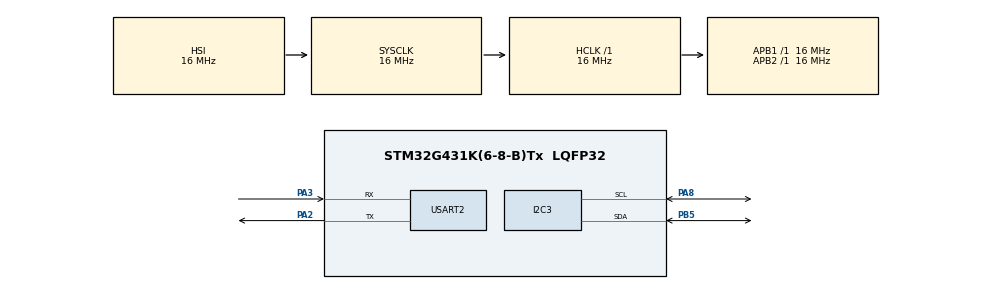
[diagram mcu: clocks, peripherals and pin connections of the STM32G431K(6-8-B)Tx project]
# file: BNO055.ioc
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Dma.I2C3_RX.0.Direction=DMA_PERIPH_TO_MEMORY
Dma.I2C3_RX.0.EventEnable=DISABLE
Dma.I2C3_RX.0.Instance=DMA1_Channel1
Dma.I2C3_RX.0.MemDataAlignment=DMA_MDATAALIGN_BYTE
Dma.I2C3_RX.0.MemInc=DMA_MINC_ENABLE
Dma.I2C3_RX.0.Mode=DMA_NORMAL
Dma.I2C3_RX.0.PeriphDataAlignment=DMA_PDATAALIGN_BYTE
Dma.I2C3_RX.0.PeriphInc=DMA_PINC_DISABLE
Dma.I2C3_RX.0.Polarity=HAL_DMAMUX_REQ_GEN_RISING
Dma.I2C3_RX.0.Priority=DMA_PRIORITY_LOW
Dma.I2C3_RX.0.RequestNumber=1
Dma.I2C3_RX.0.SignalID=NONE
Dma.I2C3_RX.0.SyncEnable=DISABLE
Dma.I2C3_RX.0.SyncPolarity=HAL_DMAMUX_SYNC_NO_EVENT
Dma.I2C3_RX.0.SyncRequestNumber=1
Dma.I2C3_RX.0.SyncSignalID=NONE
Dma.I2C3_TX.1.Direction=DMA_MEMORY_TO_PERIPH
Dma.I2C3_TX.1.EventEnable=DISABLE
Dma.I2C3_TX.1.Instance=DMA1_Channel2
Dma.I2C3_TX.1.MemDataAlignment=DMA_MDATAALIGN_BYTE
Dma.I2C3_TX.1.MemInc=DMA_MINC_ENABLE
Dma.I2C3_TX.1.Mode=DMA_NORMAL
Dma.I2C3_TX.1.PeriphDataAlignment=DMA_PDATAALIGN_BYTE
Dma.I2C3_TX.1.PeriphInc=DMA_PINC_DISABLE
Dma.I2C3_TX.1.Polarity=HAL_DMAMUX_REQ_GEN_RISING
Dma.I2C3_TX.1.Priority=DMA_PRIORITY_LOW
Dma.I2C3_TX.1.RequestNumber=1
Dma.I2C3_TX.1.SignalID=NONE
Dma.I2C3_TX.1.SyncEnable=DISABLE
Dma.I2C3_TX.1.SyncPolarity=HAL_DMAMUX_SYNC_NO_EVENT
Dma.I2C3_TX.1.SyncRequestNumber=1
Dma.I2C3_TX.1.SyncSignalID=NONE
Dma.Request0=I2C3_RX
Dma.Request1=I2C3_TX
Mcu.Family=STM32G4
Mcu.Name=STM32G431K(6-8-B)Tx
Mcu.Package=LQFP32
NVIC.DMA1_Channel1_IRQn=true\:0\:0\:false\:false\:true\:false\:true\:true
NVIC.DMA1_Channel2_IRQn=true\:0\:0\:false\:false\:true\:false\:true\:true
NVIC.PriorityGroup=NVIC_PRIORITYGROUP_4
PA2.Mode=Asynchronous
PA2.Signal=USART2_TX
PA3.Mode=Asynchronous
PA3.Signal=USART2_RX
PA8.Mode=I2C
PA8.Signal=I2C3_SCL
PB5.Mode=I2C
PB5.Signal=I2C3_SDA
ProjectManager.HeapSize=0x200
ProjectManager.StackSize=0x400
ProjectManager.TargetToolchain=STM32CubeIDE
RCC.AHBFreq_Value=16000000
RCC.APB1Freq_Value=16000000
RCC.APB1TimFreq_Value=16000000
RCC.APB2Freq_Value=16000000
RCC.APB2TimFreq_Value=16000000
RCC.CortexFreq_Value=16000000
RCC.EXTERNAL_CLOCK_VALUE=12288000
RCC.HCLKFreq_Value=16000000
RCC.HSE_VALUE=8000000
RCC.HSI48_VALUE=48000000
RCC.HSI_VALUE=16000000
RCC.LSE_VALUE=32768
RCC.SYSCLKFreq_VALUE=16000000
RCC.USBFreq_Value=64000000
RCC.VCOOutputFreq_Value=128000000
USART2.VirtualMode-Asynchronous=VM_ASYNC
board=custom

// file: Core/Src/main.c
/* USER CODE BEGIN Header */
/**
  ******************************************************************************
  * @file           : main.c
  * @brief          : Main program body
  ******************************************************************************
  * @attention
  *
  * Copyright (c) 2023 STMicroelectronics.
  * All rights reserved.
  *
  * This software is licensed under terms that can be found in the LICENSE file
  * in the root directory of this software component.
  * If no LICENSE file comes with this software, it is provided AS-IS.
  *
  ******************************************************************************
  */
/* USER CODE END Header */
#include "main.h"
#include "dma.h"
#include "i2c.h"
#include "usart.h"
#include "gpio.h"

/* USER CODE BEGIN Includes */
#include <stdio.h>
#include "bno055_stm32.h"
#ifdef __GNUC__
#define PUTCHAR_PROTOTYPE int __io_putchar(int ch)
#else
#define PUTCHAR_PROTOTYPE int fputc(int ch, FILE *f)
#endif
PUTCHAR_PROTOTYPE

{

HAL_UART_Transmit(&huart2, (uint8_t *)&ch, 1, HAL_MAX_DELAY);

return ch;

}

/* USER CODE END Includes */

void SystemClock_Config(void);
/* USER CODE BEGIN PFP */

//#ifdef __GNUC__
//#define PUTCHAR_PROTOTYPE int __io_putchar(int ch)
//#else
//#define PUTCHAR_PROTOTYPE int fputc(int ch, FILE *f)
//#endif
//
//PUTCHAR_PROTOTYPE
//
//{
//
//	HAL_UART_Transmit(&huart2, (uint8_t *)&ch, 1, HAL_MAX_DELAY);
//	return ch;
//
//}

/* USER CODE END PFP */

int main(void)
{

  /* MCU Configuration--------------------------------------------------------*/

  /* Reset of all peripherals, Initializes the Flash interface and the Systick. */
  HAL_Init();

  /* Configure the system clock */
  SystemClock_Config();

  /* Initialize all configured peripherals */
  MX_GPIO_Init();
  MX_DMA_Init();
  MX_I2C3_Init();
  MX_USART2_UART_Init();
  /* USER CODE BEGIN 2 */
//  printf("Hello\r\n");
  bno055_assignI2C(&hi2c3);
  bno055_setup();
  bno055_setOperationModeNDOF();
  /* USER CODE END 2 */

  /* Infinite loop */
  while (1)
  {
	bno055_vector_t v = bno055_getVectorEuler();
	printf("Orientation: %.2f %.2f %.2f\r\n", v.x, v.y, v.z);
//	printf("Heading: %.2f Roll: %.2f Pitch: %.2f\r\n", v.x, v.y, v.z);
//	v = bno055_getVectorQuaternion();
//	printf("W: %.2f X: %.2f Y: %.2f Z: %.2f\r\n", v.w, v.x, v.y, v.z);
	HAL_Delay(100);
  }
}

void SystemClock_Config(void)
{
  RCC_OscInitTypeDef RCC_OscInitStruct = {0};
  RCC_ClkInitTypeDef RCC_ClkInitStruct = {0};

  /** Configure the main internal regulator output voltage
  */
  HAL_PWREx_ControlVoltageScaling(PWR_REGULATOR_VOLTAGE_SCALE1);

  /** Initializes the RCC Oscillators according to the specified parameters
  * in the RCC_OscInitTypeDef structure.
  */
  RCC_OscInitStruct.OscillatorType = RCC_OSCILLATORTYPE_HSI;
  RCC_OscInitStruct.HSIState = RCC_HSI_ON;
  RCC_OscInitStruct.HSICalibrationValue = RCC_HSICALIBRATION_DEFAULT;
  RCC_OscInitStruct.PLL.PLLState = RCC_PLL_NONE;
  if (HAL_RCC_OscConfig(&RCC_OscInitStruct) != HAL_OK)
  {
    Error_Handler();
  }

  /** Initializes the CPU, AHB and APB buses clocks
  */
  RCC_ClkInitStruct.ClockType = RCC_CLOCKTYPE_HCLK|RCC_CLOCKTYPE_SYSCLK
                              |RCC_CLOCKTYPE_PCLK1|RCC_CLOCKTYPE_PCLK2;
  RCC_ClkInitStruct.SYSCLKSource = RCC_SYSCLKSOURCE_HSI;
  RCC_ClkInitStruct.AHBCLKDivider = RCC_SYSCLK_DIV1;
  RCC_ClkInitStruct.APB1CLKDivider = RCC_HCLK_DIV1;
  RCC_ClkInitStruct.APB2CLKDivider = RCC_HCLK_DIV1;

  if (HAL_RCC_ClockConfig(&RCC_ClkInitStruct, FLASH_LATENCY_0) != HAL_OK)
  {
    Error_Handler();
  }
}

void Error_Handler(void)
{
  __disable_irq();
  while (1)
  {
  }
}
